# LPC11xxLV_LPC111x_LV register map
File version: 1
CPU: CM0 r0p0, little endian, no MPU, no FPU, 2 interrupt priority bits
Registers are 32-bit, read-write, reset 0x0 unless marked. A register's access mark holds for its fields unless they carry their own. Offsets are from the block's base; [hi:lo] are bit positions; {n}, {i} and the like mark numbered series; 'fields as' and 'values as' point back to an identical list.

## I2C
Base 0x40000000
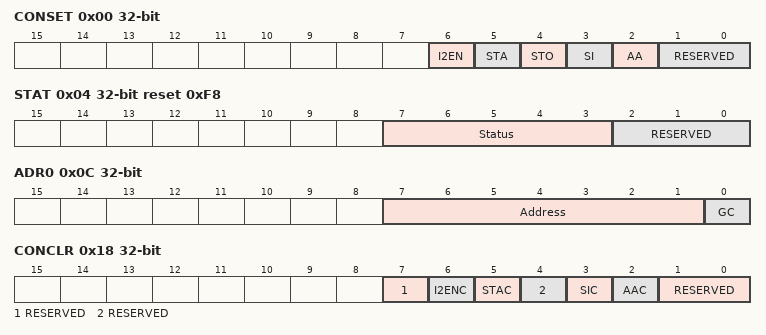
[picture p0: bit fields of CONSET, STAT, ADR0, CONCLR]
0x00 CONSET — I2C Control Set Register. When a one is written to a bit of this register, the corresponding bit in the I2C control register is set. Writing a zero has no effect on the corresponding bit in the I2C control register.
  [6] I2EN — I2C interface enable.
  [5] STA — START flag.
  [4] STO — STOP flag.
  [3] SI — I2C interrupt flag.
  [2] AA — Assert acknowledge flag.
  [1:0] RESERVED — Reserved. User software should not write ones to reserved bits. The value read from a reserved bit is not defined.
0x04 STAT ro reset 0xF8 — I2C Status Register. During I2C operation, this register provides detailed status codes that allow software to determine the next action needed.
  [7:3] Status — These bits give the actual status information about the I 2C interface.
  [2:0] RESERVED — These bits are unused and are always 0.
0x08 DAT — I2C Data Register. During master or slave transmit mode, data to be transmitted is written to this register. During master or slave receive mode, data that has been received may be read from this register.
  [7:0] Data — This register holds data values that have been received or are to be transmitted.
0x0C ADR0 — I2C Slave Address Register 0. Contains the 7-bit slave address for operation of the I2C interface in slave mode, and is not used in master mode. The least significant bit determines whether a slave responds to the General Call address.
  [7:1] Address — The I2C device address for slave mode.
  [0] GC — General Call enable bit.
0x10 SCLH reset 0x4 — SCH Duty Cycle Register High Half Word. Determines the high time of the I2C clock.
  [15:0] SCLH — Count for SCL HIGH time period selection.
0x14 SCLL reset 0x4 — SCL Duty Cycle Register Low Half Word. Determines the low time of the I2C clock. I2nSCLL and I2nSCLH together determine the clock frequency generated by an I2C master and certain times used in slave mode.
  [15:0] SCLL — Count for SCL low time period selection.
0x18 CONCLR wo reset not defined — I2C Control Clear Register. When a one is written to a bit of this register, the corresponding bit in the I2C control register is cleared. Writing a zero has no effect on the corresponding bit in the I2C control register.
  [7] RESERVED — Reserved. User software should not write ones to reserved bits. The value read from a reserved bit is not defined.
  [6] I2ENC — I2C interface Disable bit.
  [5] STAC — START flag Clear bit.
  [4] RESERVED — Reserved. User software should not write ones to reserved bits. The value read from a reserved bit is not defined.
  [3] SIC — I2C interrupt Clear bit.
  [2] AAC — Assert acknowledge Clear bit.
  [1:0] RESERVED — Reserved. User software should not write ones to reserved bits. The value read from a reserved bit is not defined.
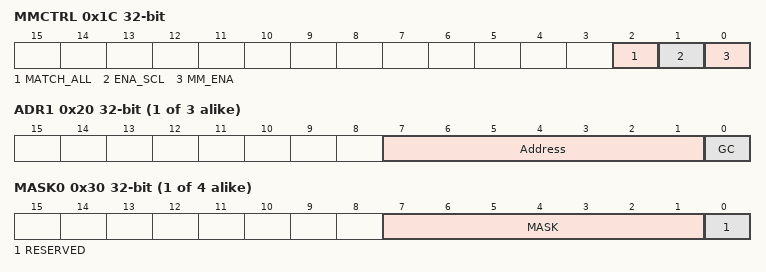
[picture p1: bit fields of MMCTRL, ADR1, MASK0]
0x1C MMCTRL — Monitor mode control register.
  [2] MATCH_ALL — Select interrupt register match.
    0=MATCH (When this bit is cleared, an interrupt will only be generated when a match occurs to one of the (up-to) four address registers described above. That is, the module will respond as a normal slave as far as address-recognition is concerned.); 1=ANYADDRESS (When this bit is set to 1 and the I2C is in monitor mode, an interrupt will be generated on ANY address received. This will enable the part to monitor all traffic on the bus.)
  [1] ENA_SCL — SCL output enable.
    0=HIGH (When this bit is cleared to 0, the SCL output will be forced high when the module is in monitor mode. As described above, this will prevent the module from having any control over the I2C clock line.); 1=NORMAL (When this bit is set, the I2C module may exercise the same control over the clock line that it would in normal operation. This means that, acting as a slave peripheral, the I2C module can stretch the clock line (hold it low) until it has had time to respond to an I2C interrupt.[1])
  [0] MM_ENA — Monitor mode enable.
    0=MONITOR_MODE_DISABLE (Monitor mode disabled.); 1=THE_I2C_MODULE_WILL_ (The I2C module will enter monitor mode. In this mode the SDA output will be forced high. This will prevent the I2C module from outputting data of any kind (including ACK) onto the I 2C data bus. Depending on the state of the ENA_SCL bit, the output may be also forced high, preventing the module from having control over the I2C clock line.)
{0x1C+4i} ADR{i} (i=1..3) — I2C Slave Address Register 1. Contains the 7-bit slave address for operation of the I2C interface in slave mode, and is not used in master mode. The least significant bit determines whether a slave responds to the General Call address.
  fields as ADR0
0x2C DATA_BUFFER ro — Data buffer register. The contents of the 8 MSBs of the I2DAT shift register will be transferred to the DATA_BUFFER automatically after every nine bits (8 bits of data plus ACK or NACK) has been received on the bus.
  [7:0] Data — This register holds contents of the 8 MSBs of the DAT shift register.
{0x30+4i} MASK{i} (i=0..3) — I2C Slave address mask register 0. This mask register is associated with I2ADR0 to determine an address match. The mask register has no effect when comparing to the General Call address (0000000).
  [7:1] MASK — Mask bits.
  [0] RESERVED — Reserved. User software should not write ones to reserved bits. This bit reads always back as 0.

## GPIO0
Base 0x50000000
Same registers: GPIO1 0x50010000, GPIO2 0x50020000, GPIO3 0x50030000
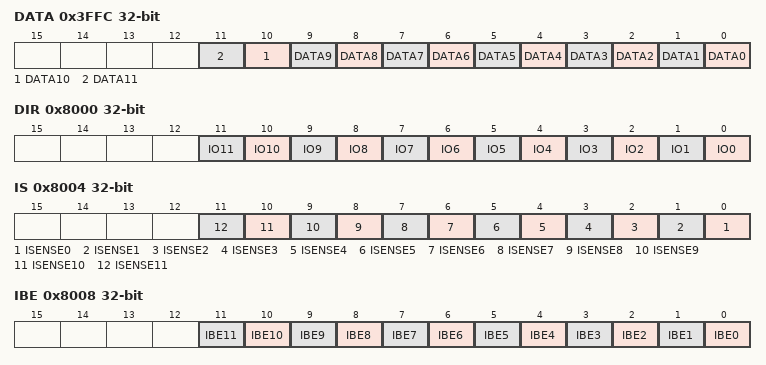
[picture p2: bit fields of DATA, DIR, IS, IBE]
0x3FFC DATA reset not defined — Port n data register for pins PIOn_0 to PIOn_11
  [n] DATA{n} (n=0..11) — Logic levels for pins PIOn_0 to PIOn_11. HIGH = 1, LOW = 0.
0x8000 DIR — Data direction register for port n
  [n] IO{n} (n=0..11) — Selects pin x as input or output (x = 0 to 11). 0 = Pin PIOn_x is configured as input. 1 = Pin PIOn_x is configured as output.
0x8004 IS — Interrupt sense register for port n
  [n] ISENSE{n} (n=0..11) — Selects interrupt on pin x as level or edge sensitive (x = 0 to 11). 0 = Interrupt on pin PIOn_x is configured as edge sensitive. 1 = Interrupt on pin PIOn_x is configured as level sensitive.
0x8008 IBE — Interrupt both edges register for port n
  [n] IBE{n} (n=0..11) — Selects interrupt on pin x to be triggered on both edges (x = 0 to 11). 0 = Interrupt on pin PIOn_x is controlled through register GPIOnIEV. 1 = Both edges on pin PIOn_x trigger an interrupt.
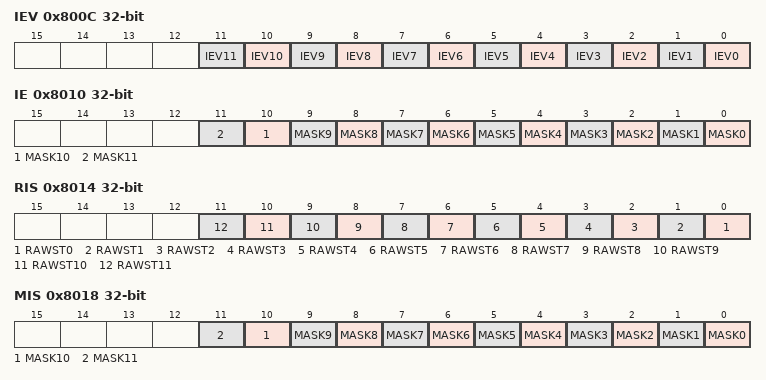
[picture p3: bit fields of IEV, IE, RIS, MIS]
0x800C IEV — Interrupt event register for port n
  [n] IEV{n} (n=0..11) — Selects interrupt on pin x to be triggered rising or falling edges (x = 0 to 11). 0 = Depending on setting in register GPIOnIS (see Table 109), falling edges or LOW level on pin PIOn_x trigger an interrupt. 1 = Depending on setting in register GPIOnIS (see Table 109), rising edges or HIGH level on pin PIOn_x trigger an interrupt.
0x8010 IE — Interrupt mask register for port n
  [n] MASK{n} (n=0..11) — Selects interrupt on pin x to be masked (x = 0 to 11). 0 = Interrupt on pin PIOn_x is masked. 1 = Interrupt on pin PIOn_x is not masked.
0x8014 RIS ro — Raw interrupt status register for port n
  [n] RAWST{n} (n=0..11) — Raw interrupt status (x = 0 to 11). 0 = No interrupt on pin PIOn_x. 1 = Interrupt requirements met on PIOn_x.
0x8018 MIS ro — Masked interrupt status register for port n
  [n] MASK{n} (n=0..11) — Selects interrupt on pin x to be masked (x = 0 to 11). 0 = No interrupt or interrupt masked on pin PIOn_x. 1 = Interrupt on PIOn_x.
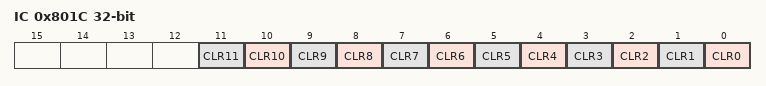
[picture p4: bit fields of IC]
0x801C IC wo — Interrupt clear register for port n
  [n] CLR{n} (n=0..11) — Selects interrupt on pin x to be cleared (x = 0 to 11). Clears the interrupt edge detection logic. This register is write-only. The synchronizer between the GPIO and the NVIC blocks causes a delay of 2 clocks. It is recommended to add two NOPs after the clear of the interrupt edge detection logic before the exit of the interrupt service routine. 0 = No effect. 1 = Clears edge detection logic for pin PIOn_x.
